# STM32N647xx register map
File version: 1.0
Registers are 32-bit, read-write, reset 0x0 unless marked. A register's access mark holds for its fields unless they carry their own. Offsets are from the block's base; [hi:lo] are bit positions; {n}, {i} and the like mark numbered series.

## RNG
Base 0x44020000
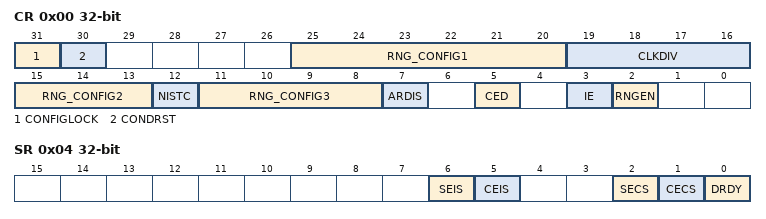
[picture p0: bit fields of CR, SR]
0x00 CR — RNG control register
  [31] CONFIGLOCK
  [30] CONDRST
  [25:20] RNG_CONFIG1
  [19:16] CLKDIV
    0=BY_1 (No clock division); 1=BY_2 (2 RNG clock cycles per internal RNG clock); 2=BY_4 (4 RNG clock cycles per internal RNG clock); 3=BY_8 (8 RNG clock cycles per internal RNG clock); 4=BY_16 (16 RNG clock cycles per internal RNG clock); 5=BY_32 (32 RNG clock cycles per internal RNG clock); 6=BY_64 (64 RNG clock cycles per internal RNG clock); 7=BY_128 (128 RNG clock cycles per internal RNG clock); 8=BY_256 (256 RNG clock cycles per internal RNG clock); 9=BY_512 (512 RNG clock cycles per internal RNG clock); 10=BY_1024 (1024 RNG clock cycles per internal RNG clock); 11=BY_2048 (2048 RNG clock cycles per internal RNG clock); 12=BY_4096 (4096 RNG clock cycles per internal RNG clock); 13=BY_8192 (8192 RNG clock cycles per internal RNG clock); 14=BY_16384 (16384 RNG clock cycles per internal RNG clock); 15=BY_32768 (32768 RNG clock cycles per internal RNG clock)
  [15:13] RNG_CONFIG2
  [12] NISTC
  [11:8] RNG_CONFIG3
  [7] ARDIS
  [5] CED
  [3] IE
  [2] RNGEN
0x04 SR — RNG status register
  [6] SEIS, [5] CEIS, [2] SECS, [1] CECS, [0] DRDY
0x08 DR — RNG data register
0x10 HTCR — RNG health test configuration register
  [31:0] HTCFG

## HASH
Base 0x44020400
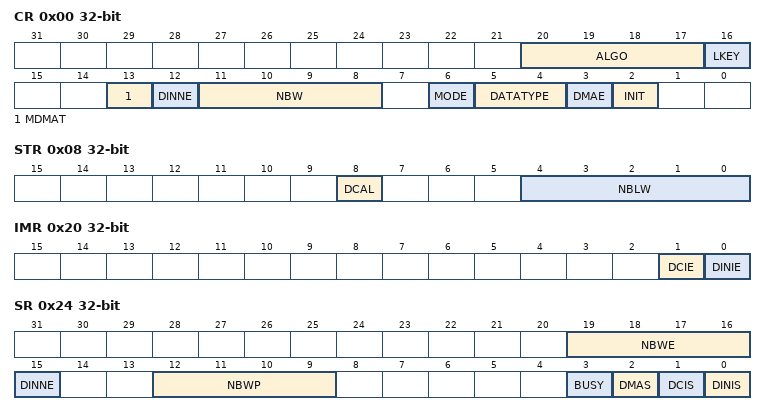
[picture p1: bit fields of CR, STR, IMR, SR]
0x00 CR — HASH control register
  [20:17] ALGO, [16] LKEY, [13] MDMAT, [12] DINNE, [11:8] NBW, [6] MODE, [5:4] DATATYPE, [3] DMAE, [2] INIT
0x04 DIN — HASH data input register
0x08 STR — HASH start register
  [8] DCAL, [4:0] NBLW
{0xC+4i} HR{i} (i=0..4) — HASH digest registers
0x20 IMR — HASH interrupt enable register
  [1] DCIE, [0] DINIE
0x24 SR — HASH status register
  [19:16] NBWE, [15] DINNE, [12:9] NBWP, [3] BUSY, [2] DMAS, [1] DCIS, [0] DINIS
{0xF8+4i} CSR[{i}] (i=0..102)
{0x310+4i} DIGEST_HR{i} (i=0..15) — HASH digest registers

## PKA
Base 0x44022000
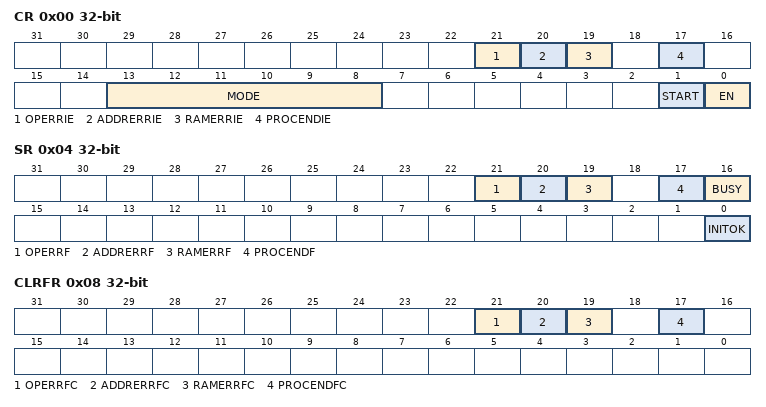
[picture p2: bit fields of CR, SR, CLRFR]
0x00 CR — PKA control register
  [21] OPERRIE — Operation Error interrupt enable
  [20] ADDRERRIE — Address error interrupt enable
  [19] RAMERRIE — RAM error interrupt enable
  [17] PROCENDIE — End of operation interrupt enable
  [13:8] MODE — MODE[5:0] PKA operation code
  [1] START — Start operation
  [0] EN — PKA enable
0x04 SR — PKA status register
  [21] OPERRF — PKA operation Error flag
  [20] ADDRERRF — Address error flag
  [19] RAMERRF — PKA RAM error flag
  [17] PROCENDF — PKA end of operation flag
  [16] BUSY — PKA operation is in progress
  [0] INITOK — PKA initialisation flag
0x08 CLRFR — PKA clear flag register
  [21] OPERRFC — Clear PKA operation Error flag
  [20] ADDRERRFC — Clear address error flag
  [19] RAMERRFC — Clear PKA RAM error flag
  [17] PROCENDFC — Clear PKA end of operation flag
{0x400+4i} RAM[{i}] (i=0..1333)

## RIFSC
Base 0x44024000
0x00 RISC_CR — RIFSC RISC slave configuration register x
  [0] GLOCK — Global lock
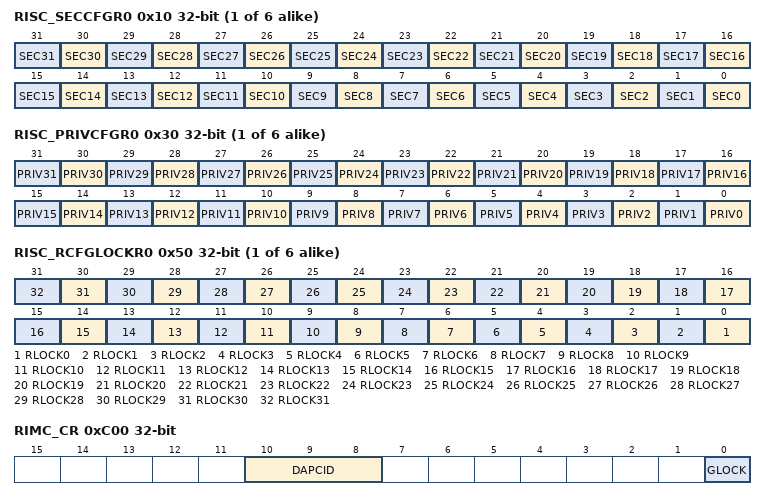
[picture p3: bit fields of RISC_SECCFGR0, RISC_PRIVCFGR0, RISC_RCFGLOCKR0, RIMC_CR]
{0x10+4i} RISC_SECCFGR{i} (i=0..5) — RIFSC RISC slave security configuration register x
  [n] SEC{n} (n=0..31) — Security configuration for peripheral {n}
{0x30+4i} RISC_PRIVCFGR{i} (i=0..5) — RIFSC RISFC slave privileged register x
  [n] PRIV{n} (n=0..31) — privileged-only access permission for peripheral {n}
{0x50+4i} RISC_RCFGLOCKR{i} (i=0..5) — RIFSC RISC slave resource configuration lock register x
  [n] RLOCK{n} (n=0..31) — Resource lock for peripheral {n}
0xC00 RIMC_CR — RIFSC RIMC master configuration register
  [10:8] DAPCID — Debug access port compartment ID
  [0] GLOCK — Global lock
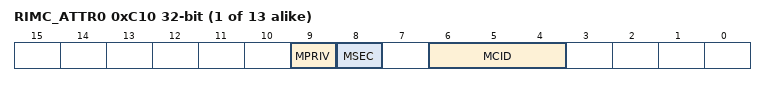
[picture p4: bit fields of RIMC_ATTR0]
{0xC10+4i} RIMC_ATTR{i} (i=0..12) — RIFSC RIMC master attribute register x
  [9] MPRIV — Master privileged
  [8] MSEC — Master secure
  [6:4] MCID — Master CID
{0xFB0+4i} PPSR{i} (i=0..5) — RIFSC peripheral protection status register x
